# MDR1986VE3 register map
Vendor: Milandr; Series: ARMCM1; File version: 2.0
ARM 32-bit Cortex-M1 Microcontroller based device, CPU clock up to 80MHz, etc.
CPU: CM1 r1p0, little endian, no MPU, no FPU, 2 interrupt priority bits
Registers are 32-bit, read-write, reset 0x0 unless marked. A register's access mark holds for its fields unless they carry their own. Offsets are from the block's base; lines under a group give offsets from that group; [hi:lo] are bit positions; {n}, {i} and the like mark numbered series; 'fields as' and 'values as' point back to an identical list; <NAME> marks a mode.

## Memory map
0x30000000 MDR_ETH1 size 0x38 — Ethernet Control
0x34000000 MDR_ETH2 size 0x38 — Ethernet Control
0x40000000 MDR_CAN1 size 0x600 — CAN Control
0x40008000 MDR_CAN2 size 0x600
0x40018000 MDR_EEPROM size 0x14 — EEPROM Control
0x40020000 MDR_RST_CLOCK size 0x40 — CLock Control
0x40028000 MDR_DMA size 0x50 — DMA Controler
0x40030000 MDR_UART1 size 0x84 — UART Control
0x40038000 MDR_UART2 size 0x84
0x40040000 MDR_SSP1 size 0x28 — Synchronous Serial Port
0x40058000 MDR_Power size 0x8 — Power Detector
0x40060000 MDR_WWDT size 0xC — Window Watchdog Timer
0x40068000 MDR_IWDT size 0x10 — Independent Watchdog Timer
0x40070000 MDR_TIMER1 size 0x90 — TIMER Control
0x40078000 MDR_TIMER2 size 0x90
0x40080000 MDR_TIMER3 size 0x90
0x40088000 MDR_ADC size 0x34 — Successive Approximation ADC
0x40098000 MDR_TIMER4 size 0x90
0x400A0000 MDR_SSP2 size 0x28
0x400A8000 MDR_PORTA size 0x2C — GPIO Port Control
0x400B0000 MDR_PORTB size 0x2C
0x400B8000 MDR_PORTC size 0x2C
0x400C0000 MDR_PORTD size 0x2C
0x400C8000 MDR_PORTE size 0x2C
0x400D8000 MDR_BKP size 0x54 — Backup and RTC Control
0x400E8000 MDR_PORTF size 0x2C
0x400F8000 MDR_SSP3 size 0x28
0x40118000 MDR_PORTG size 0x2C
0x40120000 MDR_UART3 size 0x84
0x40128000 MDR_UART4 size 0x84
0x40130000 MDR_SSP4 size 0x28
0x40138000 MDR_PORTH size 0x2C
0x40140000 MDR_PORTI size 0x2C

## MDR_EEPROM — EEPROM Control
Base 0x40018000
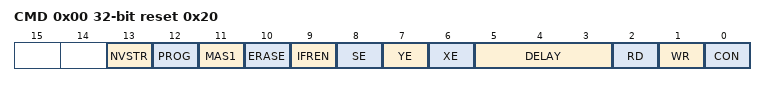
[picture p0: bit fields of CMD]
0x00 CMD reset 0x20 (reset mask 0x3FF) — EEPROM Control register
  [13] NVSTR — Memory access mode
    0=Read mode; 1=Write (Programming or erase mode)
  [12] PROG — Programm EEPROM_DI to ADDR[16:0]
    0=Inactive (No programm operation); 1=Active (Programm operation)
  [11] MAS1 — Erase whole block with ERASE
    0=Off (Disable); 1=On (Enable)
  [10] ERASE — Erase string at ADDR[16:0]
    0=Inactive (No erase operation); 1=Active (Erase operation)
  [9] IFREN — Select main or info memory
    0=Main memory; 1=Info memory
  [8] SE — RD Amplifier enable
    0=Off (Disable); 1=On (Enable)
  [7] YE — Enable ADDR[8..2]
    0=Off (Disable); 1=On (Enable)
  [6] XE — Enable ADDR[16..9]
    0=Off (Disable); 1=On (Enable)
  [5:3] DELAY — Memory access CPU delay tacts
    0=le25MHz (CPU freq is up to 25MHz); 1=le50MHz (CPU freq is up to 50MHz); 2=le75MHz (CPU freq is up to 75MHz); 3=le100MHz (CPU freq is up to 100MHz); 4=le125MHz (CPU freq is up to 125MHz); 5=le150MHz (CPU freq is up to 150MHz); 6=le175MHz (CPU freq is up to 175MHz); 7=le200MHz (CPU freq is up to 200MHz)
  [2] RD — Read operation, (test bit)
    0=Inactive (No read operation); 1=Active (Read operation)
  [1] WR — Write operation (test bit)
    0=Inactive (No write operation); 1=Active (Write operation)
  [0] CON — Enable memory access through EEPROM controller
    0=Normal access to memory; 1=Controller Access (Access to memory though registers)
0x04 ADDR — Address register
0x08 DI — Write data register
0x0C DO — Read data register
0x10 KEY — Unlock block register

## MDR_DMA — DMA Controler
Base 0x40028000
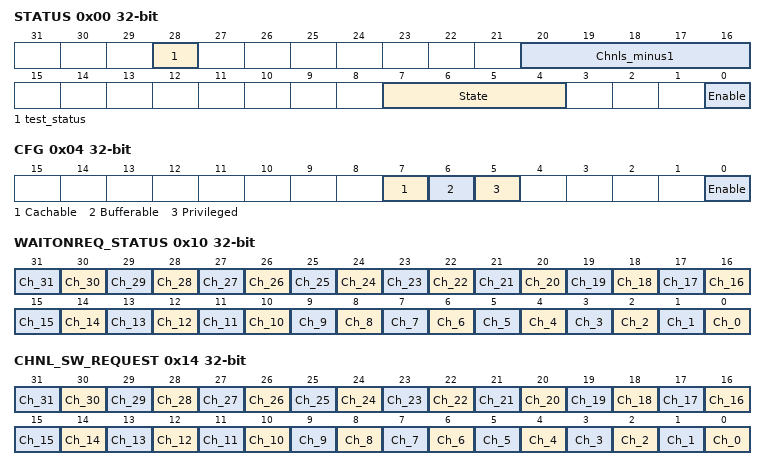
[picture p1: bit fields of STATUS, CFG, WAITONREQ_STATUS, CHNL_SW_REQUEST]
0x00 STATUS ro (reset mask 0xF01F0F01)
  [28] test_status — Test logic availability
    0=Unavailable (Test logic unavailable); 1=Available (Test logic available)
  [20:16] Chnls_minus1 — Channels count
    {v}={v+1}_channels (Channels Count) (v=0..31)
  [7:4] State — Active Operation
    0=Idle state; 1=RD_Ctrl (Reading channel controller data); 2=RD_pSrc (Reading source data end pointer); 3=RD_pDest (Reading destination data end pointer); 4=RD_Data (Reading source data); 5=WR_Data (writing destination data); 6=Wait_Clr (Waiting for DMA request to clear); 7=WR_Ctrl (Writing channel controller data); 8=Stalled transfer; 9=Done transfer; 10=ScatGath (scatter-gather transition)
  [0] Enable — Enable block
    0=Disabled (Block inactive); 1=Enabled (Block active)
0x04 CFG wo — Config register
  [7] Cachable — Cachable AHB bus priority
    0=Off (Inactive); 1=On (Active)
  [6] Bufferable — Bufferable AHB bus priority
    0=Off (Inactive); 1=On (Active)
  [5] Privileged — Privileged AHB bus priority
    0=Off (Inactive); 1=On (Active)
  [0] Enable — Enable block
    0=Disabled (Block inactive); 1=Enabled (Block active)
0x08 CTRL_BASE_PTR — Channel control data base pointer
  [31:10] Addr_Hi — Pointer
0x0C ALT_CTRL_BASE_PTR ro (reset mask 0xFFFFFC00) — Channel alternate control data base pointer
  [31:0] Addr — Pointer
0x10 WAITONREQ_STATUS ro — Channel wait on request status
  [n] Ch_{n} (n=0..31) — Channel Select
    0=Off (Inactive); 1=On (Active)
0x14 CHNL_SW_REQUEST wo write-1-sets — Channel Software Request
  fields as WAITONREQ_STATUS
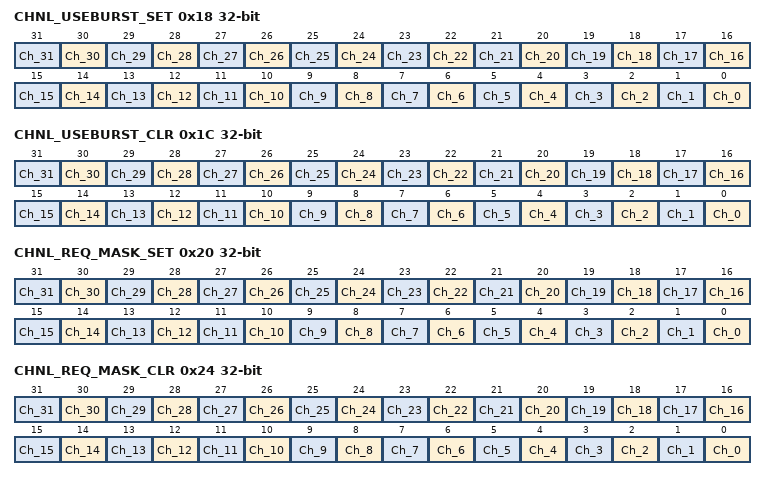
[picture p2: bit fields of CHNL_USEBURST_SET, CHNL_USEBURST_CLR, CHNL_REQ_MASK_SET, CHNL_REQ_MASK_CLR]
0x18 CHNL_USEBURST_SET write-1-sets — Disable SREQ requests
  fields as WAITONREQ_STATUS
0x1C CHNL_USEBURST_CLR wo write-1-clears — Enable SREQ requests
  fields as WAITONREQ_STATUS
0x20 CHNL_REQ_MASK_SET write-1-sets — Disable channel processing
  fields as WAITONREQ_STATUS
0x24 CHNL_REQ_MASK_CLR wo write-1-clears — Enable channel processing
  fields as WAITONREQ_STATUS
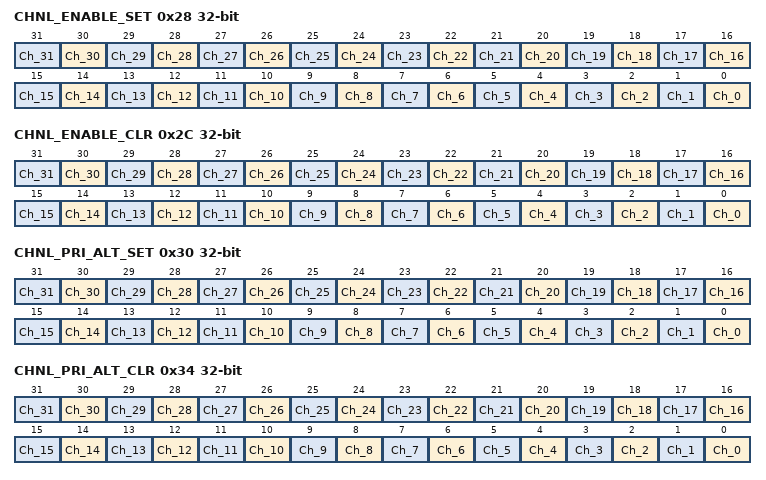
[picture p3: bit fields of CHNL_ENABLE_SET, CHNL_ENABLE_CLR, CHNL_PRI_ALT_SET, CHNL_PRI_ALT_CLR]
0x28 CHNL_ENABLE_SET write-1-sets — Start Channel
  fields as WAITONREQ_STATUS
0x2C CHNL_ENABLE_CLR wo write-1-clears — Stop Channel
  fields as WAITONREQ_STATUS
0x30 CHNL_PRI_ALT_SET write-1-sets — Select Alter Structure
  fields as WAITONREQ_STATUS
0x34 CHNL_PRI_ALT_CLR wo write-1-clears — Select Primary Structure
  fields as WAITONREQ_STATUS
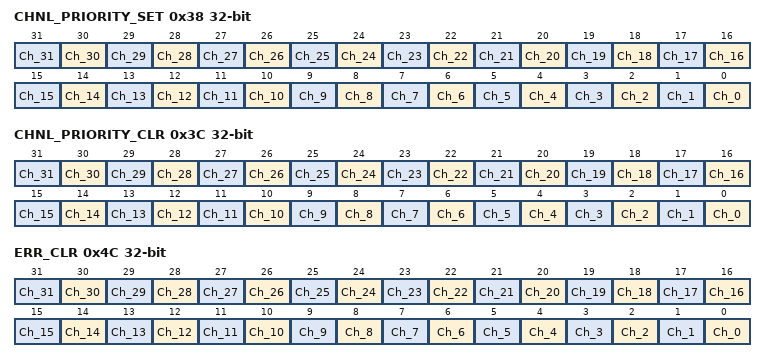
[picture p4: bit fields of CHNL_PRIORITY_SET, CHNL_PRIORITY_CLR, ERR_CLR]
0x38 CHNL_PRIORITY_SET write-1-sets — Rise up priority to High
  fields as WAITONREQ_STATUS
0x3C CHNL_PRIORITY_CLR wo write-1-clears — Clear Priority to Normal
  fields as WAITONREQ_STATUS
0x4C ERR_CLR write-1-clears — AHB-Lite bus error clear
  fields as WAITONREQ_STATUS
